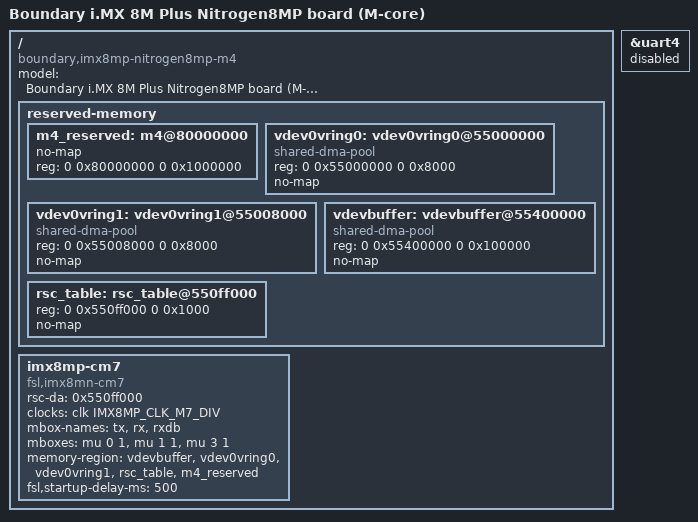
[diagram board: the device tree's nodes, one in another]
// SPDX-License-Identifier: (GPL-2.0 OR MIT)
/*
 * Copyright 2021 Boundary Devices LLC
 */

/dts-v1/;

#include "imx8mp-nitrogen8mp.dts"

/ {
	model = "Boundary i.MX 8M Plus Nitrogen8MP board (M-core)";
	compatible = "boundary,imx8mp-nitrogen8mp-m4", "fsl,imx8mp";

	reserved-memory {
		#address-cells = <2>;
		#size-cells = <2>;
		ranges;

		m4_reserved: m4@80000000 {
			no-map;
			reg = <0 0x80000000 0 0x1000000>;
		};

		vdev0vring0: vdev0vring0@55000000 {
			compatible = "shared-dma-pool";
			reg = <0 0x55000000 0 0x8000>;
			no-map;
		};

		vdev0vring1: vdev0vring1@55008000 {
			compatible = "shared-dma-pool";
			reg = <0 0x55008000 0 0x8000>;
			no-map;
		};

		vdevbuffer: vdevbuffer@55400000 {
			compatible = "shared-dma-pool";
			reg = <0 0x55400000 0 0x100000>;
			no-map;
		};

		rsc_table: rsc_table@550ff000 {
			reg = <0 0x550ff000 0 0x1000>;
			no-map;
		};
	};

	imx8mp-cm7 {
		compatible = "fsl,imx8mn-cm7";
		rsc-da = <0x550ff000>;
		clocks = <&clk IMX8MP_CLK_M7_DIV>;
		mbox-names = "tx", "rx", "rxdb";
		mboxes = <&mu 0 1
			  &mu 1 1
			  &mu 3 1>;
		memory-region = <&vdevbuffer>, <&vdev0vring0>, <&vdev0vring1>,
				<&rsc_table>, <&m4_reserved>;
		status = "okay";
		fsl,startup-delay-ms = <500>;
	};
};

&uart4 {
	status = "disabled";
};
